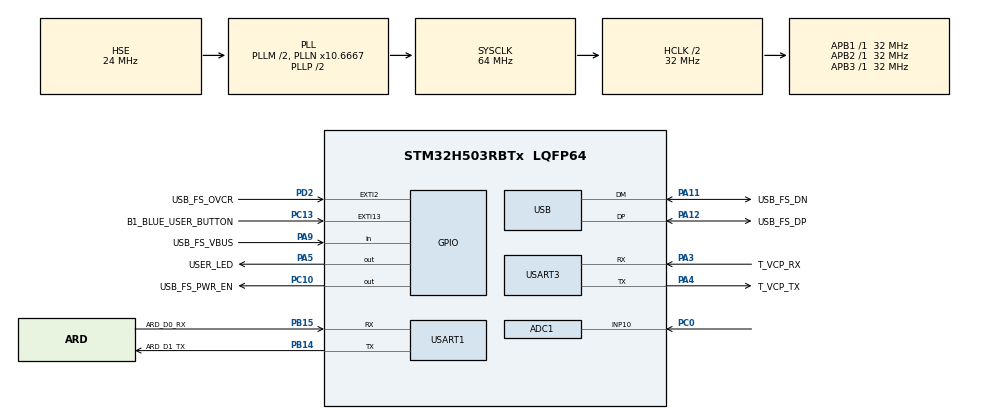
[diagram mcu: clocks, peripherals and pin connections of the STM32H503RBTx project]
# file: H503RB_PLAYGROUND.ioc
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ADC1.Channel-0\#ChannelRegularConversion=ADC_CHANNEL_10
ADC1.ClockPrescaler=ADC_CLOCK_ASYNC_DIV8
ADC1.ContinuousConvMode=ENABLE
ADC1.DMAContinuousRequests=ENABLE
ADC1.MonitoredBy-0\#ChannelRegularConversion=__NULL
ADC1.NbrOfConversion=1
ADC1.NbrOfConversionFlag=1
ADC1.OffsetNumber-0\#ChannelRegularConversion=ADC_OFFSET_NONE
ADC1.Rank-0\#ChannelRegularConversion=1
ADC1.SamplingTime-0\#ChannelRegularConversion=ADC_SAMPLETIME_640CYCLES_5
ADC1.master=1
BOOTPATH.BootPathName=LEGACY
BOOTPATH.UserSelectedBootPath=LEGACY
GPDMA1.CIRCULARMODE_GPDMACH4=ENABLE
GPDMA1.DESTDATAWIDTH_GPDMACH4=DMA_DEST_DATAWIDTH_HALFWORD
GPDMA1.IPHANDLE_GPDMACH4-SIMPLEREQUEST_GPDMACH4=__NULL
GPDMA1.REQUEST_GPDMACH4=GPDMA1_REQUEST_ADC1
GPDMA1.SRCDATAWIDTH_GPDMACH4=DMA_SRC_DATAWIDTH_HALFWORD
Mcu.Family=STM32H5
Mcu.Name=STM32H503RBTx
Mcu.Package=LQFP64
NVIC.ADC1_IRQn=true\:0\:0\:false\:false\:true\:true\:true\:true
NVIC.GPDMA1_Channel4_IRQn=true\:0\:0\:false\:false\:true\:true\:true\:true
NVIC.PriorityGroup=NVIC_PRIORITYGROUP_4
NVIC.USART1_IRQn=true\:0\:0\:false\:true\:true\:1\:true\:true\:true
PA11.GPIO_Label=USB_FS_DN
PA11.Mode=Device
PA11.Signal=USB_DM
PA12.GPIO_Label=USB_FS_DP
PA12.Mode=Device
PA12.Signal=USB_DP
PA13(JTMS/SWDIO).GPIO_Label=T_SWDIO
PA13(JTMS/SWDIO).Mode=Serial_Wire
PA13(JTMS/SWDIO).Signal=DEBUG_JTMS-SWDIO
PA14(JTCK/SWCLK).GPIO_Label=T_SWCLK
PA14(JTCK/SWCLK).Mode=Serial_Wire
PA14(JTCK/SWCLK).Signal=DEBUG_JTCK-SWCLK
PA15(JTDI).GPIO_Label=T_JTDI
PA15(JTDI).Signal=DEBUG_JTDI
PA3.GPIO_Label=T_VCP_RX
PA3.Mode=Asynchronous
PA3.Signal=USART3_RX
PA4.GPIO_Label=T_VCP_TX
PA4.Mode=Asynchronous
PA4.Signal=USART3_TX
PA5.GPIO_Label=USER_LED
PA5.Signal=GPIO_Output
PA9.GPIO_Label=USB_FS_VBUS
PA9.Signal=GPIO_Input
PB14.GPIO_Label=ARD_D1_TX
PB14.Mode=Asynchronous
PB14.Signal=USART1_TX
PB15.GPIO_Label=ARD_D0_RX
PB15.Mode=Asynchronous
PB15.Signal=USART1_RX
PB3(JTDO/TRACESWO).GPIO_Label=T_SWO
PB3(JTDO/TRACESWO).Signal=DEBUG_JTDO-SWO
PC0.Signal=ADCx_INP10
PC10.GPIO_Label=USB_FS_PWR_EN
PC10.Signal=GPIO_Output
PC13.GPIO_Label=B1_BLUE_USER_BUTTON
PC13.Signal=GPXTI13
PC14-OSC32_IN(OSC32_IN).Mode=LSE-External-Oscillator
PC14-OSC32_IN(OSC32_IN).Signal=RCC_OSC32_IN
PC15-OSC32_OUT(OSC32_OUT).Mode=LSE-External-Oscillator
PC15-OSC32_OUT(OSC32_OUT).Signal=RCC_OSC32_OUT
PD2.GPIO_Label=USB_FS_OVCR
PD2.Signal=GPXTI2
PH0-OSC_IN(PH0).Mode=HSE-External-Oscillator
PH0-OSC_IN(PH0).Signal=RCC_OSC_IN
PH1-OSC_OUT(PH1).Mode=HSE-External-Oscillator
PH1-OSC_OUT(PH1).Signal=RCC_OSC_OUT
ProjectManager.HeapSize=0x200
ProjectManager.StackSize=0x400
ProjectManager.TargetToolchain=STM32CubeIDE
RCC.ADCFreq_Value=32000244.140625
RCC.AHBCLKDivider=RCC_SYSCLK_DIV2
RCC.AHBFreq_Value=32000244.140625
RCC.APB1Freq_Value=32000244.140625
RCC.APB1TimFreq_Value=32000244.140625
RCC.APB2Freq_Value=32000244.140625
RCC.APB2TimFreq_Value=32000244.140625
RCC.APB3Freq_Value=32000244.140625
RCC.CSI_VALUE=4000000
RCC.CortexFreq_Value=32000244.140625
RCC.EPOD_VALUE=24000000
RCC.HCLKFreq_Value=32000244.140625
RCC.HSE_VALUE=24000000
RCC.HSI48_VALUE=48000000
RCC.HSIDiv=RCC_HSI_DIV1
RCC.HSI_VALUE=64000000
RCC.LSIRC_VALUE=32000
RCC.PLLFRACN=5462
RCC.PLLM=2
RCC.PLLN=10
RCC.PLLSourceVirtual=RCC_PLL1_SOURCE_HSE
RCC.SYSCLKFreq_VALUE=64000488.28125
RCC.SYSCLKSource=RCC_SYSCLKSOURCE_PLLCLK
RCC.USBFreq_Value=48000000
RCC.VCOOutputFreq_Value=128000976.5625
SH.ADCx_INP10.0=ADC1_INP10,IN10-Single-Ended
USART1.VirtualMode=VM_ASYNC
USART3.VirtualMode=VM_ASYNC
USB.VirtualMode=Device_Only
VP_BOOTPATH_VS_BOOTPATH.Mode=BP_Activate
VP_GPDMA1_VS_GPDMACH4.Mode=SIMPLEREQUEST_GPDMACH4
VP_ICACHE_VS_ICACHE.Mode=DefaultMode
VP_MEMORYMAP_VS_MEMORYMAP.Mode=CurAppReg
VP_PWR_VS_DBSignals.Mode=DisableDeadBatterySignals
VP_PWR_VS_LPOM.Mode=PowerOptimisation
VP_PWR_VS_SECSignals.Mode=Security/Privilege
board=NUCLEO-H503RB

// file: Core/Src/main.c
/* USER CODE BEGIN Header */
/**
  ******************************************************************************
  * @file           : main.c
  * @brief          : Main program body
  ******************************************************************************
  * @attention
  *
  * Copyright (c) 2024 STMicroelectronics.
  * All rights reserved.
  *
  * This software is licensed under terms that can be found in the LICENSE file
  * in the root directory of this software component.
  * If no LICENSE file comes with this software, it is provided AS-IS.
  *
  ******************************************************************************
  */
/* USER CODE END Header */
#include "main.h"
#include "adc.h"
#include "gpdma.h"
#include "icache.h"
#include "memorymap.h"
#include "usart.h"
#include "usb.h"
#include "gpio.h"

void SystemClock_Config(void);
static void MX_NVIC_Init(void);

/* USER CODE BEGIN 0 */
	volatile uint16_t buffer;
	volatile float value;
/* USER CODE END 0 */

int main(void)
{

  /* MCU Configuration--------------------------------------------------------*/

  /* Reset of all peripherals, Initializes the Flash interface and the Systick. */
  HAL_Init();

  /* Configure the system clock */
  SystemClock_Config();

  /* Initialize all configured peripherals */
  MX_GPIO_Init();
  MX_GPDMA1_Init();
  MX_USART1_UART_Init();
  MX_ICACHE_Init();
  MX_USB_PCD_Init();
  MX_ADC1_Init();
  MX_USART3_UART_Init();

  /* Initialize interrupts */
  MX_NVIC_Init();
  /* USER CODE BEGIN 2 */
  HAL_ADCEx_Calibration_Start(&hadc1, ADC_SINGLE_ENDED);
  HAL_ADC_Start_DMA(&hadc1, &buffer, 1);
  /* USER CODE END 2 */

  /* Infinite loop */
  /* USER CODE BEGIN WHILE */
  while (1)
  {
	  value = (float)(buffer/4096.0)*3.3f;
    /* USER CODE END WHILE */

  }
}

void SystemClock_Config(void)
{
  RCC_OscInitTypeDef RCC_OscInitStruct = {0};
  RCC_ClkInitTypeDef RCC_ClkInitStruct = {0};

  /** Configure the main internal regulator output voltage
  */
  __HAL_PWR_VOLTAGESCALING_CONFIG(PWR_REGULATOR_VOLTAGE_SCALE3);

  while(!__HAL_PWR_GET_FLAG(PWR_FLAG_VOSRDY)) {}

  /** Initializes the RCC Oscillators according to the specified parameters
  * in the RCC_OscInitTypeDef structure.
  */
  RCC_OscInitStruct.OscillatorType = RCC_OSCILLATORTYPE_HSI48|RCC_OSCILLATORTYPE_HSE;
  RCC_OscInitStruct.HSEState = RCC_HSE_ON;
  RCC_OscInitStruct.HSI48State = RCC_HSI48_ON;
  RCC_OscInitStruct.PLL.PLLState = RCC_PLL_ON;
  RCC_OscInitStruct.PLL.PLLSource = RCC_PLL1_SOURCE_HSE;
  RCC_OscInitStruct.PLL.PLLM = 2;
  RCC_OscInitStruct.PLL.PLLN = 10;
  RCC_OscInitStruct.PLL.PLLP = 2;
  RCC_OscInitStruct.PLL.PLLQ = 2;
  RCC_OscInitStruct.PLL.PLLR = 2;
  RCC_OscInitStruct.PLL.PLLRGE = RCC_PLL1_VCIRANGE_3;
  RCC_OscInitStruct.PLL.PLLVCOSEL = RCC_PLL1_VCORANGE_WIDE;
  RCC_OscInitStruct.PLL.PLLFRACN = 5462;
  if (HAL_RCC_OscConfig(&RCC_OscInitStruct) != HAL_OK)
  {
    Error_Handler();
  }

  /** Initializes the CPU, AHB and APB buses clocks
  */
  RCC_ClkInitStruct.ClockType = RCC_CLOCKTYPE_HCLK|RCC_CLOCKTYPE_SYSCLK
                              |RCC_CLOCKTYPE_PCLK1|RCC_CLOCKTYPE_PCLK2
                              |RCC_CLOCKTYPE_PCLK3;
  RCC_ClkInitStruct.SYSCLKSource = RCC_SYSCLKSOURCE_PLLCLK;
  RCC_ClkInitStruct.AHBCLKDivider = RCC_SYSCLK_DIV2;
  RCC_ClkInitStruct.APB1CLKDivider = RCC_HCLK_DIV1;
  RCC_ClkInitStruct.APB2CLKDivider = RCC_HCLK_DIV1;
  RCC_ClkInitStruct.APB3CLKDivider = RCC_HCLK_DIV1;

  if (HAL_RCC_ClockConfig(&RCC_ClkInitStruct, FLASH_LATENCY_3) != HAL_OK)
  {
    Error_Handler();
  }
}

/**
  * @brief NVIC Configuration.
  * @retval None
  */
static void MX_NVIC_Init(void)
{
  /* USART1_IRQn interrupt configuration */
  HAL_NVIC_SetPriority(USART1_IRQn, 0, 0);
  HAL_NVIC_EnableIRQ(USART1_IRQn);
}

void Error_Handler(void)
{
  __disable_irq();
  while (1)
  {
  }
}
